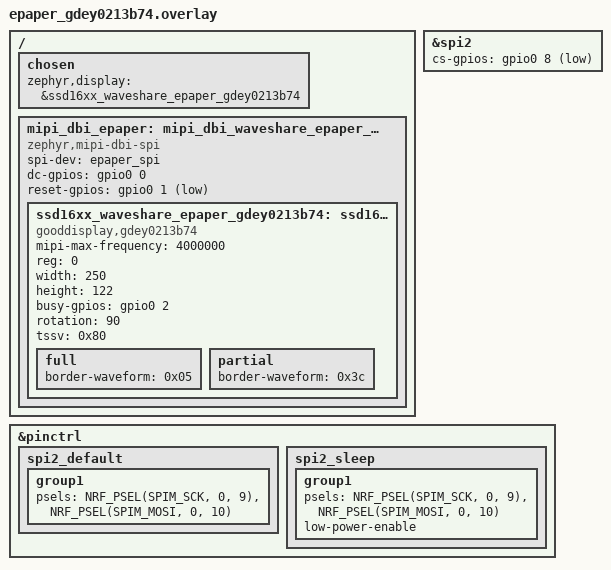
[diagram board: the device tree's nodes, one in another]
/*
 * Copyright (c) 2024, Kelly Helmut Lord
 *
 * SPDX-License-Identifier: Apache-2.0
 */


/ {
	chosen {
		zephyr,display = &ssd16xx_waveshare_epaper_gdey0213b74;
	};

	mipi_dbi_epaper: mipi_dbi_waveshare_epaper_gdey0213b74 {
		compatible = "zephyr,mipi-dbi-spi";
		spi-dev = <&epaper_spi>;
		dc-gpios = <&gpio0 0 GPIO_ACTIVE_HIGH>;
		reset-gpios = <&gpio0 1 GPIO_ACTIVE_LOW>;
		#address-cells = <1>;
		#size-cells = <0>;

		ssd16xx_waveshare_epaper_gdey0213b74: ssd16xxfb@0 {
			compatible = "gooddisplay,gdey0213b74", "solomon,ssd1680";
			mipi-max-frequency = <4000000>;
			reg = <0>;
			width = <250>;
			height = <122>;
			busy-gpios = <&gpio0 2 GPIO_ACTIVE_HIGH>;
            rotation = <90>;

			tssv = <0x80>;

			full {
				border-waveform = <0x05>;
			};

			partial {
				border-waveform = <0x3c>;
			};
		};
	};
};



epaper_spi: &spi2 {
    status = "okay";
    cs-gpios = <&gpio0 8 GPIO_ACTIVE_LOW>;
};

&pinctrl {
    spi2_default: spi2_default {
        group1 {
            psels = <NRF_PSEL(SPIM_SCK, 0, 9)>,
                    <NRF_PSEL(SPIM_MOSI, 0, 10)>;
        };
    };

    spi2_sleep: spi2_sleep {
        group1 {
            psels = <NRF_PSEL(SPIM_SCK, 0, 9)>,
                    <NRF_PSEL(SPIM_MOSI, 0, 10)>;
            low-power-enable;
        };
    };
};
